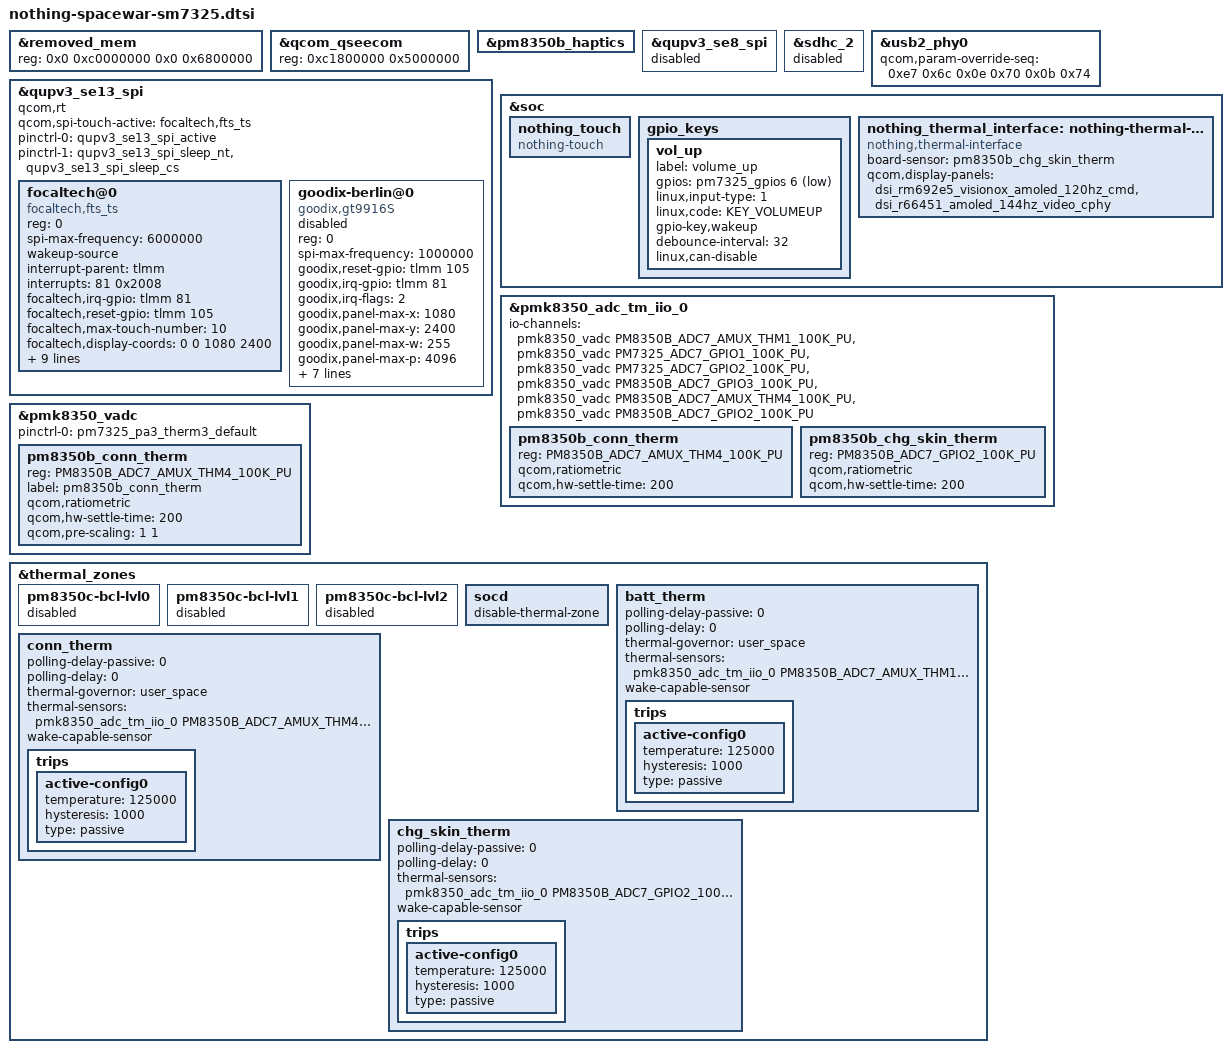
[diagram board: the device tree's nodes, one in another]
// SPDX-License-Identifier: GPL-2.0-only
/* Nothing Phone (1) "spacewar" - SM7325 device overlay */

#include <dt-bindings/gpio/gpio.h>
#include <dt-bindings/input/input.h>
#include <dt-bindings/iio/qcom,spmi-adc7-pm7325.h>
#include <dt-bindings/iio/qcom,spmi-adc7-pm8350b.h>

#include "yupik-abra-common-overlay.dtsi"
#include "nothing-spacewar-pinctrl.dtsi"
#include "nothing-spacewar-audio-overlay.dtsi"
#include "nothing-sm7325-common.dtsi"

&removed_mem {
	reg = <0x0 0xc0000000 0x0 0x6800000>;
};

&qcom_qseecom {
	reg = <0xc1800000 0x5000000>;
	reg-names = "secapp-region";
};

&pm8350b_haptics {
	status = "okay";
};

/* IR LED bus not present */
&qupv3_se8_spi {
	status = "disabled";
};

&sdhc_2 {
	status = "disabled";
};

&usb2_phy0 {
	qcom,param-override-seq =
		<0xe7 0x6c	/* override_x0 */
		 0x0e 0x70	/* override_x1 */
		 0x0b 0x74>;	/* override_x2 */
};

/*
 * Touch (SE13 SPI)
 * Only one touch node may be enabled. For a Goodix unit, swap both
 * status lines and set qcom,spi-touch-active to "goodix,brl-d".
 */
&qupv3_se13_spi {
	status = "okay";
	qcom,rt;
	qcom,spi-touch-active = "focaltech,fts_ts";
	pinctrl-names = "default", "sleep";
	pinctrl-0 = <&qupv3_se13_spi_active>;
	pinctrl-1 = <&qupv3_se13_spi_sleep_nt &qupv3_se13_spi_sleep_cs>;
	#address-cells = <1>;
	#size-cells = <0>;

	/* FocalTech FT5662 */
	focaltech@0 {
		status = "okay";
		compatible = "focaltech,fts_ts";
		reg = <0>;
		spi-max-frequency = <6000000>;
		wakeup-source;

		interrupt-parent = <&tlmm>;
		interrupts = <81 0x2008>;

		focaltech,irq-gpio = <&tlmm 81 0x2008>;
		focaltech,reset-gpio = <&tlmm 105 0x00>;
		focaltech,max-touch-number = <10>;
		focaltech,display-coords = <0 0 1080 2400>;
		focaltech,ic-type = <0x3658d488>;

		vdd-supply   = <&L3C>;
		avdd-supply  = <&L3C>;
		iovdd-supply = <&L8C>;

		panel = <&dsi_rm692e5_visionox_amoled_120hz_cmd
			 &dsi_r66451_amoled_144hz_video_cphy>;

		pinctrl-names = "pmx_ts_active", "pmx_ts_suspend", "pmx_ts_release";
		pinctrl-0 = <&ts_active>;
		pinctrl-1 = <&ts_int_suspend &ts_reset_suspend>;
		pinctrl-2 = <&ts_release>;
	};

	/* Goodix GT9916S (Berlin-D) */
	goodix-berlin@0 {
		status = "disabled";
		compatible = "goodix,gt9916S", "goodix,brl-d";
		reg = <0>;
		spi-max-frequency = <1000000>;

		goodix,reset-gpio = <&tlmm 105 0x00>;
		goodix,irq-gpio   = <&tlmm 81 0x2800>;
		goodix,irq-flags  = <2>;
		goodix,panel-max-x = <1080>;
		goodix,panel-max-y = <2400>;
		goodix,panel-max-w = <255>;
		goodix,panel-max-p = <4096>;
		goodix,pen-enable;
		goodix,firmware-name = "goodix_firmware.bin";
		goodix,config-name   = "goodix_cfg_group.bin";
		goodix,avdd-name  = "avdd";
		goodix,iovdd-name = "iovdd";

		avdd-supply  = <&L3C>;
		iovdd-supply = <&L8C>;
	};
};

&soc {
	nothing_touch {
		compatible = "nothing-touch";
		status = "okay";
	};

	gpio_keys {
		vol_up {
			label = "volume_up";
			gpios = <&pm7325_gpios 6 GPIO_ACTIVE_LOW>;
			linux,input-type = <1>;
			linux,code = <KEY_VOLUMEUP>;
			gpio-key,wakeup;
			debounce-interval = <32>;
			linux,can-disable;
		};
	};

	nothing_thermal_interface: nothing-thermal-interface {
		compatible = "nothing,thermal-interface";
		board-sensor = "pm8350b_chg_skin_therm";
		qcom,display-panels = <&dsi_rm692e5_visionox_amoled_120hz_cmd
				       &dsi_r66451_amoled_144hz_video_cphy>;
	};
};

/* io-channels fully replaces the base list; adds conn (THM4) and chg_skin (GPIO2) */
&pmk8350_adc_tm_iio_0 {
	io-channels = <&pmk8350_vadc PM8350B_ADC7_AMUX_THM1_100K_PU>,
		      <&pmk8350_vadc PM7325_ADC7_GPIO1_100K_PU>,
		      <&pmk8350_vadc PM7325_ADC7_GPIO2_100K_PU>,
		      <&pmk8350_vadc PM8350B_ADC7_GPIO3_100K_PU>,
		      <&pmk8350_vadc PM8350B_ADC7_AMUX_THM4_100K_PU>,
		      <&pmk8350_vadc PM8350B_ADC7_GPIO2_100K_PU>;

	pm8350b_conn_therm {
		reg = <PM8350B_ADC7_AMUX_THM4_100K_PU>;
		qcom,ratiometric;
		qcom,hw-settle-time = <200>;
	};

	pm8350b_chg_skin_therm {
		reg = <PM8350B_ADC7_GPIO2_100K_PU>;
		qcom,ratiometric;
		qcom,hw-settle-time = <200>;
	};
};

/* batt_therm and chg_skin_therm already defined in the base */
&pmk8350_vadc {
	pinctrl-names = "default";
	pinctrl-0 = <&pm7325_pa3_therm3_default>;

	pm8350b_conn_therm {
		reg = <PM8350B_ADC7_AMUX_THM4_100K_PU>;
		label = "pm8350b_conn_therm";
		qcom,ratiometric;
		qcom,hw-settle-time = <200>;
		qcom,pre-scaling = <1 1>;
	};
};

&thermal_zones {
	/* no valid ADC data */
	pm8350c-bcl-lvl0 {
		status = "disabled";
	};

	pm8350c-bcl-lvl1 {
		status = "disabled";
	};

	pm8350c-bcl-lvl2 {
		status = "disabled";
	};

	socd {
		disable-thermal-zone;
	};

	batt_therm {
		polling-delay-passive = <0>;
		polling-delay = <0>;
		thermal-governor = "user_space";
		thermal-sensors = <&pmk8350_adc_tm_iio_0 PM8350B_ADC7_AMUX_THM1_100K_PU>;
		wake-capable-sensor;

		trips {
			active-config0 {
				temperature = <125000>;
				hysteresis = <1000>;
				type = "passive";
			};
		};
	};

	conn_therm {
		polling-delay-passive = <0>;
		polling-delay = <0>;
		thermal-governor = "user_space";
		thermal-sensors = <&pmk8350_adc_tm_iio_0 PM8350B_ADC7_AMUX_THM4_100K_PU>;
		wake-capable-sensor;

		trips {
			active-config0 {
				temperature = <125000>;
				hysteresis = <1000>;
				type = "passive";
			};
		};
	};

	chg_skin_therm {
		polling-delay-passive = <0>;
		polling-delay = <0>;
		thermal-sensors = <&pmk8350_adc_tm_iio_0 PM8350B_ADC7_GPIO2_100K_PU>;
		wake-capable-sensor;

		trips {
			active-config0 {
				temperature = <125000>;
				hysteresis = <1000>;
				type = "passive";
			};
		};
	};
};

